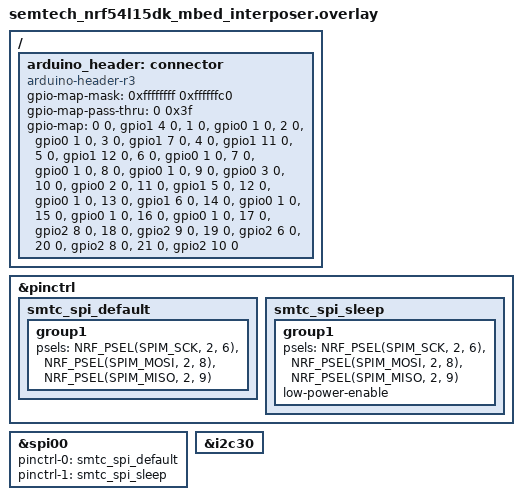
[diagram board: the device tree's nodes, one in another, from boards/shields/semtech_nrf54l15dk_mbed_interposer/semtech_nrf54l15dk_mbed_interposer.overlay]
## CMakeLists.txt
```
# Copyright (c) 2025 Semtech Corporation
# SPDX-License-Identifier: BSD-3-Clause-Clear

cmake_minimum_required(VERSION 3.13.1)
find_package(Zephyr REQUIRED HINTS $ENV{ZEPHYR_BASE})
project(radio_test_cli)

set(CLI_DIR ${ZEPHYR_USP_MODULE_DIR}/examples/main_examples/radio_test_cli)
set(HAL_DIR ${CMAKE_CURRENT_SOURCE_DIR}/src/smtc_hal_zephyr)

# Stack region code paths (from USP module)
set(USP_DIR ${ZEPHYR_USP_MODULE_DIR})
set(STACK_REAL_DIR ${USP_DIR}/protocols/lbm_lib/smtc_modem_core/lr1mac/src/smtc_real/src)
set(STACK_LR1MAC_DIR ${USP_DIR}/protocols/lbm_lib/smtc_modem_core/lr1mac/src)
set(STACK_SERVICES_DIR ${USP_DIR}/protocols/lbm_lib/smtc_modem_core/lr1mac/src/services)

target_sources(app PRIVATE
    # Shared CLI sources (same .c files as Linux/baremetal)
    ${CLI_DIR}/main_radio_test.c
    ${CLI_DIR}/cli_parser.c
    ${CLI_DIR}/cli_state.c
    ${CLI_DIR}/linenoise.c
    ${CLI_DIR}/region.c
    ${CLI_DIR}/test_modes.c
    ${CLI_DIR}/per_counter.c
    ${CLI_DIR}/mod_lora.c
    ${CLI_DIR}/stack_lbt.c
    ${CLI_DIR}/stack_region.c
    ${CLI_DIR}/platform_zephyr.c
    # Stack region sources (unmodified, from USP module)
    # NOTE: stack_hal_shim.c is NOT compiled — usp_zephyr's smtc_modem_hal.c
    # provides the same functions (smtc_modem_hal_get_time_in_ms, etc.)
    # NOTE: smtc_duty_cycle.c is NOT compiled — usp_zephyr module builds it
    ${STACK_REAL_DIR}/region_us_915.c
    ${STACK_REAL_DIR}/region_eu_868.c
    ${STACK_REAL_DIR}/region_as_923.c
    ${STACK_LR1MAC_DIR}/lr1mac_utilities.c
    # Zephyr HAL bridge (radio context from DT, DIO IRQ bridge)
    ${CMAKE_CURRENT_SOURCE_DIR}/src/zephyr_hal_bridge.c
    # Zephyr HAL implementations
    ${HAL_DIR}/smtc_hal_mcu.c
    ${HAL_DIR}/smtc_hal_gpio.c
    ${HAL_DIR}/smtc_hal_spi.c
    ${HAL_DIR}/smtc_hal_uart.c
    ${HAL_DIR}/smtc_hal_rtc.c
    ${HAL_DIR}/smtc_hal_watchdog.c
    # NOTE: smtc_hal_led.c NOT compiled — usp_zephyr subsys/usp/ provides it
    ${HAL_DIR}/smtc_hal_rng.c
    ${HAL_DIR}/smtc_hal_trace.c
    ${HAL_DIR}/smtc_hal_lp_timer.c
    ${HAL_DIR}/smtc_hal_button.c
    ${HAL_DIR}/smtc_hal_flash.c
)

# Chip-specific sources — auto-detected from device tree via Kconfig.
# The shield's DT compatible (e.g. "semtech,lr2021") sets CONFIG_SEMTECH_LR20XX
# automatically.  BSP files (ral_*_bsp.c, radio_utilities.c) are NOT compiled
# here — usp_zephyr's drivers/usp/ provides DT-based versions.
if(CONFIG_SEMTECH_LR20XX)
    target_sources(app PRIVATE ${CLI_DIR}/chip_lr20xx.c ${CLI_DIR}/mod_flrc.c)
elseif(CONFIG_SEMTECH_LR11XX)
    target_sources(app PRIVATE ${CLI_DIR}/chip_lr11xx.c)
elseif(CONFIG_SEMTECH_SX126X)
    target_sources(app PRIVATE ${CLI_DIR}/chip_sx126x.c)
else()
    message(FATAL_ERROR "No supported radio detected in device tree. "
        "Use a shield that defines a semtech,lr20xx / lr11xx / sx126x node.")
endif()

# IMPORTANT: HAL_DIR must come BEFORE the subsys/usp include of smtc_hal_linux
# (which adds Linux-specific smtc_hal_gpio_pin_names.h).  target_include_directories
# with BEFORE PUBLIC takes precedence over zephyr_include_directories.
target_include_directories(app BEFORE PUBLIC ${HAL_DIR})

zephyr_include_directories(
    ${CLI_DIR}
    ${CMAKE_CURRENT_SOURCE_DIR}/src
    ${USP_DIR}/examples/radio_hal
    ${USP_DIR}/examples
    # Stack region headers
    ${STACK_REAL_DIR}
    ${STACK_LR1MAC_DIR}
    ${STACK_SERVICES_DIR}
    ${USP_DIR}/protocols/lbm_lib/smtc_modem_core/smtc_modem_crypto/smtc_secure_element
    ${USP_DIR}/smtc_rac_lib/radio_planner/src
    ${USP_DIR}/smtc_rac_lib/smtc_ral/src
    ${USP_DIR}/smtc_rac_lib/smtc_ralf/src
)

# Compile definitions for stack region code
target_compile_definitions(app PRIVATE
    REGION_US_915
    REGION_EU_868
    REGION_AS_923
    RP2_103
    MODEM_HAL_DBG_TRACE=0
)

# Radio family + chip variant defines — auto-detected from device tree.
# The family define (LR20XX, LR11XX, SX126X) is already set globally by
# usp_zephyr's modules/usp_drivers/*.cmake.  We add chip-specific variant
# defines that radio_test_cli uses for conditional compilation.
if(CONFIG_DT_HAS_SEMTECH_LR2021_ENABLED)
    target_compile_definitions(app PRIVATE LR2021)
elseif(CONFIG_DT_HAS_SEMTECH_LR2022_ENABLED)
    target_compile_definitions(app PRIVATE LR2022)
elseif(CONFIG_DT_HAS_SEMTECH_LR1110_ENABLED)
    target_compile_definitions(app PRIVATE LR1110)
elseif(CONFIG_DT_HAS_SEMTECH_LR1120_ENABLED)
    target_compile_definitions(app PRIVATE LR1120)
elseif(CONFIG_DT_HAS_SEMTECH_LR1121_ENABLED)
    target_compile_definitions(app PRIVATE LR1121)
elseif(CONFIG_DT_HAS_SEMTECH_SX1261_NEW_ENABLED)
    target_compile_definitions(app PRIVATE SX1261)
elseif(CONFIG_DT_HAS_SEMTECH_SX1262_NEW_ENABLED)
    target_compile_definitions(app PRIVATE SX1262)
elseif(CONFIG_DT_HAS_SEMTECH_SX1268_NEW_ENABLED)
    target_compile_definitions(app PRIVATE SX1268)
endif()

# Float printf is enabled via CONFIG_NEWLIB_LIBC_FLOAT_PRINTF=y in prj.conf
```

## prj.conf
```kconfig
# Copyright (c) 2025 Semtech Corporation
# SPDX-License-Identifier: BSD-3-Clause-Clear

# Console
CONFIG_CONSOLE=y
CONFIG_UART_CONSOLE=y
CONFIG_UART_INTERRUPT_DRIVEN=y

# Peripherals
CONFIG_SPI=y
CONFIG_GPIO=y

# No Zephyr shell — we use linenoise
CONFIG_SHELL=n

# Memory
CONFIG_HEAP_MEM_POOL_SIZE=8192
CONFIG_MAIN_STACK_SIZE=4096

# C library (newlib for reliable float printf and strdup)
CONFIG_NEWLIB_LIBC=y
CONFIG_NEWLIB_LIBC_NANO=y
CONFIG_NEWLIB_LIBC_FLOAT_PRINTF=y

# Watchdog disabled
CONFIG_WATCHDOG=n

# Entropy for RNG
CONFIG_ENTROPY_GENERATOR=y

# USP framework
CONFIG_LORA_BASICS_MODEM_DRIVERS=y
CONFIG_LORA_BASICS_MODEM_DRIVERS_EVENT_TRIGGER_NO_THREAD=y
CONFIG_USP=y

# Debug
CONFIG_LOG=y
CONFIG_LOG_MODE_IMMEDIATE=y
```

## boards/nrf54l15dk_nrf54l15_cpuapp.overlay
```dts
/*
 * Device tree overlay for radio_test_cli on nRF54L15 DK.
 *
 * Radio pin configuration is provided by the shield overlay
 * (e.g. semtech_nrf54l15dk_mbed_interposer + semtech_lr1110mb1xxs).
 * This file adds UART console routing — the DK's J-Link virtual COM
 * port is on uart30, not the default uart20.
 *
 * Copyright (c) 2025 Semtech Corporation
 * SPDX-License-Identifier: BSD-3-Clause-Clear
 */

/ {
	chosen {
		zephyr,console    = &uart30;
		zephyr,shell-uart = &uart30;
	};
};

&uart20 {
	status = "disabled";
};

&spi00 {
	mx25r64: mx25r6435f@0 {
		status = "disabled";
	};
};

&uart30 {
	status = "okay";
	current-speed = <115200>;
	pinctrl-0 = <&uart30_default>;
	pinctrl-1 = <&uart30_sleep>;
	pinctrl-names = "default", "sleep";
	/delete-property/ hw-flow-control;
};
```

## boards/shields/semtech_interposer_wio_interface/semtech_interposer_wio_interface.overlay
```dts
/*
 * Copyright (c) 2025 Semtech Corporation
 *
 * SPDX-License-Identifier: Apache-2.0
 *
 * Maps WIO shield xiao_d/xiao_spi to arduino_header for use with the
 * semtech_nrf54l15dk_mbed_interposer board adapter.
 *
 * Differs from semtech_mbed_wio_interface in one entry:
 *   xiao_d[0] (DIO) → arduino_header[11] (D5) instead of arduino_header[1] (A1)
 *
 * On the original mbed_interface A1 and D5 are the same physical pin, so
 * semtech_mbed_wio_interface worked by accident.  On this interposer they
 * are different pins: A1 is NC and D5 carries LR_DIO9.
 */

/ {
    xiao_d: connectorXiao {
        compatible = "semtech,mbed-wio-interface";
        #gpio-cells = <2>;
        gpio-map-mask = <0xffffffff 0xffffffc0>;
        gpio-map-pass-thru = <0 0x3f>;
        gpio-map = <0 0 &arduino_header 11 0>, /* D0 → D5 (LR_DIO9) */
                   <1 0 &arduino_header 9 0>,  /* D1 → D3 (LR_BUSY) */
                   <2 0 &arduino_header 0 0>,  /* D2 → A0 (LR_NRESET) */
                   <3 0 &arduino_header 13 0>, /* D3 → D7 (LR_NSS) */
                   <4 0 &arduino_header 15 0>, /* D4 → D9 */
                   <5 0 &arduino_header 21 0>, /* D5 → D15 */
                   <6 0 &arduino_header 3 0>,  /* D6 → A3 (LR_LNA_CTRL) */
                   <7 0 &arduino_header 14 0>, /* D7 → D8 */
                   <8 0 &arduino_header 19 0>, /* D8 → D13 */
                   <9 0 &arduino_header 18 0>, /* D9 → D12 */
                   <10 0 &arduino_header 17 0>; /* D10 → D11 */
    };
};

xiao_spi: &arduino_spi {};
xiao_i2c: &arduino_i2c {};
```

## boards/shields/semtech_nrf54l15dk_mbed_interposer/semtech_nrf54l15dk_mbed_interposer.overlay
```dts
/*
 * Copyright (c) 2025 Semtech Corporation
 *
 * SPDX-License-Identifier: Apache-2.0
 *
 * Interposer board mapping nRF54L15 DK pins to Arduino/mbed shield header.
 * Use with: --shield semtech_nrf54l15dk_mbed_interposer --shield semtech_lr1110mb1xxs
 */

/ {
    arduino_header: connector {
        compatible = "arduino-header-r3";
        #gpio-cells = <2>;
        gpio-map-mask = <0xffffffff 0xffffffc0>;
        gpio-map-pass-thru = <0 0x3f>;
        gpio-map =  <0 0 &gpio1 4 0>,      /* A0  - LR_NRESET   */
                    <1 0 &gpio0 1 0>,      /* A1  - NC -> LED1  */
                    <2 0 &gpio0 1 0>,      /* A2  - NC -> LED1  */
                    <3 0 &gpio1 7 0>,      /* A3  - LR_LNA_CTRL */
                    <4 0 &gpio1 11 0>,     /* A4  - LR_LED_TX   */
                    <5 0 &gpio1 12 0>,     /* A5  - LR_LED_RX   */
                    <6 0 &gpio0 1 0>,      /* D0  - NC -> LED1  */
                    <7 0 &gpio0 1 0>,      /* D1  - NC -> LED1  */
                    <8 0 &gpio0 1 0>,      /* D2  - NC -> LED1  */
                    <9 0 &gpio0 3 0>,      /* D3  - LR_BUSY     */
                    <10 0 &gpio0 2 0>,     /* D4  - LR_SNIFFING */
                    <11 0 &gpio1 5 0>,     /* D5  - LR_DIO9     */
                    <12 0 &gpio0 1 0>,     /* D6  - NC -> LED1  */
                    <13 0 &gpio1 6 0>,     /* D7  - LR_NSS      */
                    <14 0 &gpio0 1 0>,     /* D8  - NC -> LED1  */
                    <15 0 &gpio0 1 0>,     /* D9  - NC -> LED1  */
                    <16 0 &gpio0 1 0>,     /* D10 - NC -> LED1  */
                    <17 0 &gpio2 8 0>,     /* D11 - LR_MOSI     */
                    <18 0 &gpio2 9 0>,     /* D12 - LR_MISO     */
                    <19 0 &gpio2 6 0>,     /* D13 - LR_SCK      */
                    <20 0 &gpio2 8 0>,     /* D14 - LR_I2C_SDA  */
                    <21 0 &gpio2 10 0>;    /* D15 - LR_I2C_SCL  */
    };
};

&pinctrl {
    smtc_spi_default: smtc_spi_default {
        group1 {
            psels = <NRF_PSEL(SPIM_SCK, 2, 6)>,
                    <NRF_PSEL(SPIM_MOSI, 2, 8)>,
                    <NRF_PSEL(SPIM_MISO, 2, 9)>;
        };
    };

    smtc_spi_sleep: smtc_spi_sleep {
        group1 {
            psels = <NRF_PSEL(SPIM_SCK, 2, 6)>,
                    <NRF_PSEL(SPIM_MOSI, 2, 8)>,
                    <NRF_PSEL(SPIM_MISO, 2, 9)>;
            low-power-enable;
        };
    };

};

arduino_spi: &spi00 {
    status = "okay";
    pinctrl-0 = <&smtc_spi_default>;
    pinctrl-1 = <&smtc_spi_sleep>;
    pinctrl-names = "default", "sleep";
};

/* Label alias required by semtech_mbed_wio_interface — not enabled */
arduino_i2c: &i2c30 {};
```

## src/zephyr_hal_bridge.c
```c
/**
 * @file      zephyr_hal_bridge.c
 *
 * @brief     Zephyr HAL bridge for radio_test_cli
 *
 * Bridges the CLI's HAL expectations to Zephyr's device tree model:
 *   - Sets the radio driver context from DT (for chip_lr20xx.c)
 *   - Bridges the usp_zephyr driver's DIO IRQ to the GPIO HAL callback table
 *   - Provides BSP stubs not yet available in usp_zephyr
 *
 * radio_test_cli bypasses RAC and talks directly to the LR20xx driver.
 * It does NOT use SMTC_SW_PLATFORM_INIT() or CONFIG_USP_MAIN_THREAD
 * because there is no RAC engine to run.
 *
 * The Clear BSD License
 * Copyright Semtech Corporation 2025. All rights reserved.
 */

#include "zephyr_hal_bridge.h"

#include <zephyr/kernel.h>
#include <zephyr/device.h>
#include <zephyr/drivers/gpio.h>

#include <stdint.h>

#include <zephyr/usp/lora_lbm_transceiver.h>

#include "chip_interface.h"
#include "smtc_hal_gpio.h"
#include "smtc_hal_gpio_pin_names.h"
#include "modem_pinout.h"

/*
 * --- Compile-time validation ------------------------------------------------
 *
 * modem_pinout_zephyr.h hardcodes pin values (due to include-path conflicts
 * with smtc_hal_linux headers added globally by usp_zephyr).  Verify they
 * match the enum in smtc_hal_gpio_pin_names.h.
 */
_Static_assert( RADIO_NSS == ZEPHYR_PIN_RADIO_NSS, "RADIO_NSS pin mismatch" );
_Static_assert( RADIO_NRST == ZEPHYR_PIN_RADIO_NRST, "RADIO_NRST pin mismatch" );
_Static_assert( RADIO_BUSY_PIN == ZEPHYR_PIN_RADIO_BUSY, "RADIO_BUSY_PIN pin mismatch" );
_Static_assert( RADIO_DIO_MAIN == ZEPHYR_PIN_RADIO_DIO, "RADIO_DIO_MAIN pin mismatch" );
_Static_assert( SMTC_LED_TX == ZEPHYR_PIN_LED_TX, "SMTC_LED_TX pin mismatch" );
_Static_assert( SMTC_LED_RX == ZEPHYR_PIN_LED_RX, "SMTC_LED_RX pin mismatch" );

/*
 * --- DIO IRQ bridge ---------------------------------------------------------
 *
 * main_radio_test.c calls hal_gpio_irq_attach(RADIO_DIO_MAIN, callback) which
 * stores the callback in the GPIO HAL's pin table.  On Zephyr, the usp_zephyr
 * driver owns the DIO interrupt.  We bridge it: the driver calls our wrapper,
 * which fires the callback via hal_gpio_fire_irq().
 */
static void zephyr_dio_irq_wrapper( const struct device* dev )
{
    ( void ) dev;
    hal_gpio_fire_irq( ZEPHYR_PIN_RADIO_DIO );
}

/*
 * --- XOSC trim stub ---------------------------------------------------------
 *
 * usp_zephyr's BSP does not provide ral_lr20xx_bsp_get_xosc_trim() because
 * the DT binding doesn't have XTA/XTB properties yet.  Provide defaults here
 * until the DT binding is extended (see plan TODO U1).
 */
void ral_lr20xx_bsp_get_xosc_trim( const void* context, uint8_t* xta, uint8_t* xtb, uint8_t* wait_time_us )
{
    ( void ) context;
    *xta          = 0x05;  /* default XTA trim */
    *xtb          = 0x05;  /* default XTB trim */
    *wait_time_us = 100;   /* default XOSC stabilization delay */
}

/*
 * --- Radio device from device tree ------------------------------------------
 *
 * The usp_zephyr driver auto-instantiates a struct device for each LR20xx
 * node via DT_FOREACH_STATUS_OKAY.  The lr20xx_hal.c functions cast the
 * context to (const struct device*) and access dev->config / dev->data.
 * We just need to get that device pointer and pass it to chip_set_radio_context().
 */

/* Use the same DT chosen node that all usp_zephyr samples use.
 * The shield overlay defines: zephyr,lorawan-transceiver = &lora_semtech_wio_lr20xx;
 * This makes the bridge radio-agnostic (works with LR2021, LR2022, etc.) */
#define RADIO_NODE DT_CHOSEN( zephyr_lorawan_transceiver )

void zephyr_hal_bridge_init( void )
{
    /* Get the Zephyr device for the radio (instantiated by the driver from DT) */
    const struct device* radio_dev = DEVICE_DT_GET( RADIO_NODE );

    if( !device_is_ready( radio_dev ) )
    {
        printk( "FATAL: radio device not ready\n" );
        k_panic( );
    }

    /* Pass the device pointer as the radio context.
     * lr20xx_hal.c casts this to (const struct device*) and reads
     * dev->config (lr20xx_hal_context_cfg_t) for SPI/GPIO specs. */
    chip_set_radio_context( radio_dev );

    /* Bridge DIO IRQ: attach our wrapper to the usp_zephyr driver's IRQ,
     * then enable it.  When main_radio_test.c calls hal_gpio_irq_attach()
     * the callback is stored in the GPIO HAL pin table.  When the DIO
     * fires, the driver calls zephyr_dio_irq_wrapper() which fires
     * the stored callback via hal_gpio_fire_irq(ZEPHYR_PIN_RADIO_DIO). */
    lora_transceiver_board_attach_interrupt( radio_dev, zephyr_dio_irq_wrapper );
    lora_transceiver_board_enable_interrupt( radio_dev );
}
```

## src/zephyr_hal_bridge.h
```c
/**
 * @file      zephyr_hal_bridge.h
 *
 * @brief     Zephyr HAL bridge for radio_test_cli
 *
 * The Clear BSD License
 * Copyright Semtech Corporation 2025. All rights reserved.
 */
#ifndef ZEPHYR_HAL_BRIDGE_H
#define ZEPHYR_HAL_BRIDGE_H

/**
 * Initialize the bridge between radio_test_cli's HAL expectations and
 * the Zephyr device tree model.  Called from hal_mcu_init().
 *
 * - Sets the radio driver context from DT (for chip_lr20xx.c)
 * - Bridges the usp_zephyr driver's DIO IRQ to the GPIO HAL callback table
 */
void zephyr_hal_bridge_init( void );

#endif /* ZEPHYR_HAL_BRIDGE_H */
```
